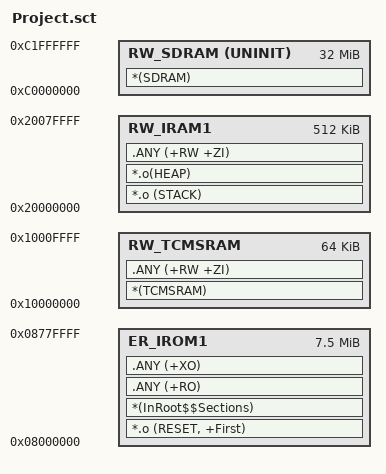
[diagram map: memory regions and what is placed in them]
; *************************************************************
; *** Scatter-Loading Description File generated by uVision ***
; *************************************************************

LR_IROM1 0x08000000 0x00780000  {    ; load region size_region
  ER_IROM1 0x08000000 0x00780000  {  ; load address = execution address
   *.o (RESET, +First)
   *(InRoot$$Sections)
   .ANY (+RO)
   .ANY (+XO)
  }
  RW_IRAM1 0x20000000 0x00080000  {  ; RW data
    *.o (STACK)
	*.o(HEAP)
   .ANY (+RW +ZI)
  }
  RW_TCMSRAM 0x10000000 0x10000  {  ; TCMSRAM 64KB
   *(TCMSRAM)
   .ANY (+RW +ZI)
  }

  RW_SDRAM 0xC0000000 UNINIT 0x2000000  {  ; SDRAM 32MB
    *(SDRAM)

  }
}

